# DISPC_OVR1 register map
Vendor: Texas Instruments
Peripheral module from a debugger description file (folder 66AK2G0x_66AK2G1x).
Registers are 32-bit, access per field, reset 0x0 unless marked. A register's access mark holds for its fields unless they carry their own. Offsets are as the file gives them; lines under a group give offsets from that group; [hi:lo] are bit positions; {n}, {i} and the like mark numbered series; 'fields as' and 'values as' point back to an identical list; <NAME> marks a mode.

## DISPC_OVR1
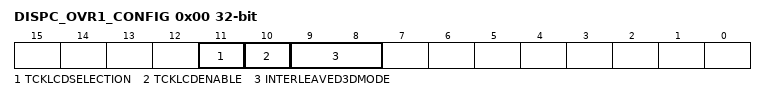
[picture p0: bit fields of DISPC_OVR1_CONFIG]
0x00 DISPC_OVR1_CONFIG
  [11] TCKLCDSELECTION rw — Transparency Color Key Selection Shadow bit-field. 0h (R/W) = Destination transparency color key selected 1h (R/W) = Source transparency color key selected
  [10] TCKLCDENABLE rw — Transparency Color Key Enabled Shadow bit-field. 0h (R/W) = Disable the transparency color key 1h (R/W) = Enable the transparency color key
  [9:8] INTERLEAVED3DMODE rw — Define which layer contributes to odd/even lines of the line interleaving 3D format 0h (R/W) = No interleaving happens in the overlay manager 1h (R/W) = RESERVED 2h (R/W) = At even lines (all pixels) have a contribution from even z-order pipes and odd lines (all pixels) have a contribution from the odd z-order pipes. 3h (R/W) = A even pixels (for all lines) have a contribution from even z-order pipes and odd pixels (for all lines) have a contribution from the odd z-order pipes
0x08 DISPC_OVR1_DEFAULT_COLOR rw
  [31:0] DEFAULTCOLOR — 48-bit ARGB color value to specify the default solid color to display when there is no data from the overlays. Only [31-0] is defined in this register. Refer to DEFAULT_COLOR2 for [47-32] bits.
0x0C DISPC_OVR1_DEFAULT_COLOR2
  [15:0] DEFAULTCOLOR rw — 48-bit ARGB color value to specify the default solid color to display when there is no data from the overlays. Only [47-32] is defined in this register. refer to DEFAULT_COLOR for [31-0] bits
0x10 DISPC_OVR1_TRANS_COLOR_MAX rw
  [31:0] TRANSCOLORKEY — [31-0] Transparency Color Key Value in 36-bit RGB format
0x14 DISPC_OVR1_TRANS_COLOR_MAX2
  [3:0] TRANSCOLORKEY rw — [35-32] Transparency Color Key Value in 36-bit RGB format
0x18 DISPC_OVR1_TRANS_COLOR_MIN rw
  fields as DISPC_OVR1_TRANS_COLOR_MAX
0x1C DISPC_OVR1_TRANS_COLOR_MIN2
  fields as DISPC_OVR1_TRANS_COLOR_MAX2
